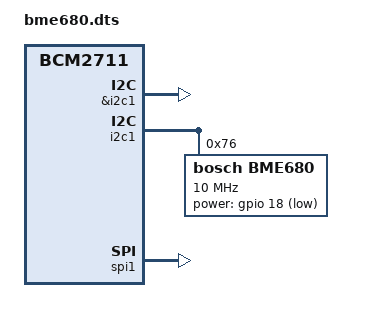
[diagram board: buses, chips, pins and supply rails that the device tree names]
/dts-v1/;
/plugin/;

/ {
    compatible = "brcm,bcm2711"; /* Raspberry Pi 4B */

    fragment@0 {
        target = <&i2c1>;
        __overlay__ {
            #address-cells = <1>;
            #size-cells = <0>;
            status = "okay";

            bme680: sensor@76 {
                compatible = "bosch,bme680";
                reg = <0x76>;
                bosch,heater-temp = <320>;
                bosch,heater-duration = <150>;
                bosch,heater-current = <10>;
                power-gpios = <&gpio 18 1>;
                debounce-delay-us = <100>;
                gas-threshold-ohms = <100000>;
                netlink-group = <1>;
                spi-max-frequency = <10000000>;
                status = "okay";
            };
        };
    };

    &i2c1 {
        status = "okay";
    };

    fragment@1 {
        target = <&spi1>;
        __overlay__ {
            status = "okay";
            bme680_spi: bme680@0 {
                compatible = "bosch,bme680";
                reg = <0>;
                spi-max-frequency = <10000000>;
                status = "disabled";
            };
        };
    };
};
